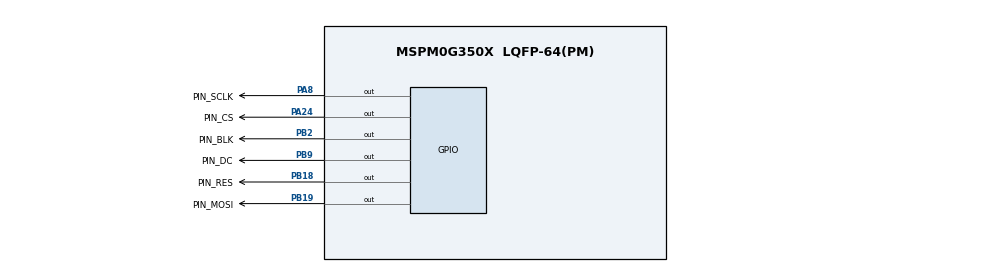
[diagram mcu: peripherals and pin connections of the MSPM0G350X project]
/**
 * @cliArgs --device "MSPM0G350X" --part "Default" --package "LQFP-64(PM)" --product "mspm0_sdk@2.04.00.06"
 * @versions {"tool":"1.23.0+4000"}
 */

/**
 * Import the modules used in this configuration.
 */
const GPIO   = scripting.addModule("/ti/driverlib/GPIO", {}, false);
const GPIO1  = GPIO.addInstance();
const SYSCTL = scripting.addModule("/ti/driverlib/SYSCTL");

/**
 * Write custom configuration values to the imported modules.
 */
GPIO1.$name                         = "GPIO_LCD";
GPIO1.associatedPins.create(6);
GPIO1.associatedPins[0].$name       = "PIN_SCLK";
GPIO1.associatedPins[0].pin.$assign = "PA8";
GPIO1.associatedPins[1].$name       = "PIN_MOSI";
GPIO1.associatedPins[1].pin.$assign = "PB19";
GPIO1.associatedPins[2].$name       = "PIN_RES";
GPIO1.associatedPins[2].pin.$assign = "PB18";
GPIO1.associatedPins[3].$name       = "PIN_DC";
GPIO1.associatedPins[3].pin.$assign = "PB9";
GPIO1.associatedPins[4].$name       = "PIN_CS";
GPIO1.associatedPins[4].pin.$assign = "PA24";
GPIO1.associatedPins[5].$name       = "PIN_BLK";
GPIO1.associatedPins[5].pin.$assign = "PB2";

const Board = scripting.addModule("/ti/driverlib/Board", {}, false);

SYSCTL.forceDefaultClkConfig = true;

/**
 * Pinmux solution for unlocked pins/peripherals. This ensures that minor changes to the automatic solver in a future
 * version of the tool will not impact the pinmux you originally saw.  These lines can be completely deleted in order to
 * re-solve from scratch.
 */
Board.peripheral.$suggestSolution          = "DEBUGSS";
Board.peripheral.swclkPin.$suggestSolution = "PA20";
Board.peripheral.swdioPin.$suggestSolution = "PA19";
SYSCTL.peripheral.$suggestSolution         = "SYSCTL";
